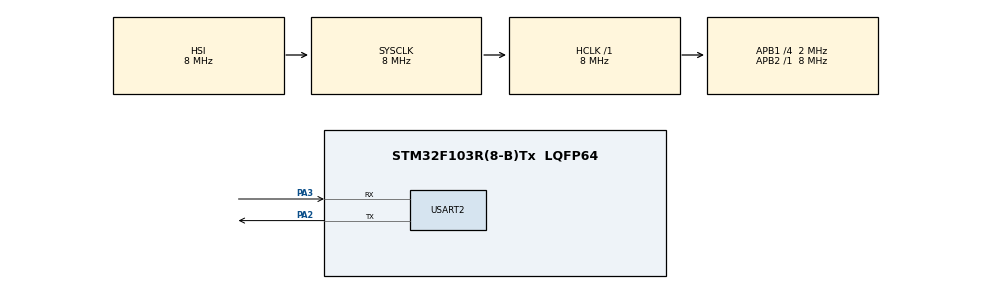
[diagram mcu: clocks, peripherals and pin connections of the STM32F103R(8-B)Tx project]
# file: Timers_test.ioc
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Mcu.Family=STM32F1
Mcu.Name=STM32F103R(8-B)Tx
Mcu.Package=LQFP64
NVIC.PriorityGroup=NVIC_PRIORITYGROUP_4
PA2.Mode=Asynchronous
PA2.Signal=USART2_TX
PA3.Mode=Asynchronous
PA3.Signal=USART2_RX
ProjectManager.HeapSize=0x200
ProjectManager.StackSize=0x400
ProjectManager.TargetToolchain=MDK-ARM V5
RCC.AHBFreq_Value=8000000
RCC.APB1CLKDivider=RCC_HCLK_DIV4
RCC.APB1Freq_Value=2000000
RCC.APB1TimFreq_Value=4000000
RCC.APB2Freq_Value=8000000
RCC.APB2TimFreq_Value=8000000
RCC.HCLKFreq_Value=8000000
RCC.RTCClockSelection=RCC_RTCCLKSOURCE_LSE
RCC.SYSCLKFreq_VALUE=8000000
RCC.USBFreq_Value=8000000
TIM2.ClockDivision=TIM_CLOCKDIVISION_DIV1
TIM2.Period=65535
TIM2.Prescaler=40-1
USART2.VirtualMode=VM_ASYNC
VP_SYS_VS_ND.Mode=No_Debug
VP_TIM2_VS_ClockSourceINT.Mode=Internal
board=NUCLEO-F103RB

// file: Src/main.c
/* USER CODE BEGIN Header */
/**
  ******************************************************************************
  * @file           : main.c
  * @brief          : Main program body
  ******************************************************************************
  ** This notice applies to any and all portions of this file
  * that are not between comment pairs USER CODE BEGIN and
  * USER CODE END. Other portions of this file, whether
  * inserted by the user or by software development tools
  * are owned by their respective copyright owners.
  *
  * COPYRIGHT(c) 2019 STMicroelectronics
  *
  * Redistribution and use in source and binary forms, with or without modification,
  * are permitted provided that the following conditions are met:
  *   1. Redistributions of source code must retain the above copyright notice,
  *      this list of conditions and the following disclaimer.
  *   2. Redistributions in binary form must reproduce the above copyright notice,
  *      this list of conditions and the following disclaimer in the documentation
  *      and/or other materials provided with the distribution.
  *   3. Neither the name of STMicroelectronics nor the names of its contributors
  *      may be used to endorse or promote products derived from this software
  *      without specific prior written permission.
  *
  * THIS SOFTWARE IS PROVIDED BY THE COPYRIGHT HOLDERS AND CONTRIBUTORS "AS IS"
  * AND ANY EXPRESS OR IMPLIED WARRANTIES, INCLUDING, BUT NOT LIMITED TO, THE
  * IMPLIED WARRANTIES OF MERCHANTABILITY AND FITNESS FOR A PARTICULAR PURPOSE ARE
  * DISCLAIMED. IN NO EVENT SHALL THE COPYRIGHT HOLDER OR CONTRIBUTORS BE LIABLE
  * FOR ANY DIRECT, INDIRECT, INCIDENTAL, SPECIAL, EXEMPLARY, OR CONSEQUENTIAL
  * DAMAGES (INCLUDING, BUT NOT LIMITED TO, PROCUREMENT OF SUBSTITUTE GOODS OR
  * SERVICES; LOSS OF USE, DATA, OR PROFITS; OR BUSINESS INTERRUPTION) HOWEVER
  * CAUSED AND ON ANY THEORY OF LIABILITY, WHETHER IN CONTRACT, STRICT LIABILITY,
  * OR TORT (INCLUDING NEGLIGENCE OR OTHERWISE) ARISING IN ANY WAY OUT OF THE USE
  * OF THIS SOFTWARE, EVEN IF ADVISED OF THE POSSIBILITY OF SUCH DAMAGE.
  *
  ******************************************************************************
  */
/* USER CODE END Header */

#include "main.h"

/* USER CODE BEGIN Includes */
#include <string.h>
/* USER CODE END Includes */

TIM_HandleTypeDef htim2;

UART_HandleTypeDef huart2;

void SystemClock_Config(void);
static void MX_GPIO_Init(void);
static void MX_TIM2_Init(void);
static void MX_USART2_UART_Init(void);

int main(void)
{

  /* MCU Configuration--------------------------------------------------------*/

  /* Reset of all peripherals, Initializes the Flash interface and the Systick. */
  HAL_Init();

  /* Configure the system clock */
  SystemClock_Config();

  /* Initialize all configured peripherals */
  MX_GPIO_Init();
  MX_TIM2_Init();
  MX_USART2_UART_Init();
  /* USER CODE BEGIN 2 */

	char transmit[20];

	HAL_TIM_Base_Start(&htim2);

	uint16_t last_time = 0;

  /* USER CODE END 2 */

  /* Infinite loop */
  while (1)
  {

    /* USER CODE BEGIN 3 */
		sprintf(transmit, "%u\r\n", (uint16_t)(TIM2->CNT - last_time));
		last_time = TIM2->CNT;
		HAL_UART_Transmit(&huart2, (uint8_t*)transmit, strlen(transmit), 10);

		HAL_Delay(100);
  }
  /* USER CODE END 3 */
}

void SystemClock_Config(void)
{
  RCC_OscInitTypeDef RCC_OscInitStruct = {0};
  RCC_ClkInitTypeDef RCC_ClkInitStruct = {0};

  /**Initializes the CPU, AHB and APB busses clocks
  */
  RCC_OscInitStruct.OscillatorType = RCC_OSCILLATORTYPE_HSI;
  RCC_OscInitStruct.HSIState = RCC_HSI_ON;
  RCC_OscInitStruct.HSICalibrationValue = RCC_HSICALIBRATION_DEFAULT;
  RCC_OscInitStruct.PLL.PLLState = RCC_PLL_NONE;
  if (HAL_RCC_OscConfig(&RCC_OscInitStruct) != HAL_OK)
  {
    Error_Handler();
  }
  /**Initializes the CPU, AHB and APB busses clocks
  */
  RCC_ClkInitStruct.ClockType = RCC_CLOCKTYPE_HCLK|RCC_CLOCKTYPE_SYSCLK
                              |RCC_CLOCKTYPE_PCLK1|RCC_CLOCKTYPE_PCLK2;
  RCC_ClkInitStruct.SYSCLKSource = RCC_SYSCLKSOURCE_HSI;
  RCC_ClkInitStruct.AHBCLKDivider = RCC_SYSCLK_DIV1;
  RCC_ClkInitStruct.APB1CLKDivider = RCC_HCLK_DIV4;
  RCC_ClkInitStruct.APB2CLKDivider = RCC_HCLK_DIV1;

  if (HAL_RCC_ClockConfig(&RCC_ClkInitStruct, FLASH_LATENCY_0) != HAL_OK)
  {
    Error_Handler();
  }
}

static void MX_TIM2_Init(void)
{

  TIM_ClockConfigTypeDef sClockSourceConfig = {0};
  TIM_MasterConfigTypeDef sMasterConfig = {0};

  htim2.Instance = TIM2;
  htim2.Init.Prescaler = 40-1;
  htim2.Init.CounterMode = TIM_COUNTERMODE_UP;
  htim2.Init.Period = 65535;
  htim2.Init.ClockDivision = TIM_CLOCKDIVISION_DIV1;
  htim2.Init.AutoReloadPreload = TIM_AUTORELOAD_PRELOAD_DISABLE;
  if (HAL_TIM_Base_Init(&htim2) != HAL_OK)
  {
    Error_Handler();
  }
  sClockSourceConfig.ClockSource = TIM_CLOCKSOURCE_INTERNAL;
  if (HAL_TIM_ConfigClockSource(&htim2, &sClockSourceConfig) != HAL_OK)
  {
    Error_Handler();
  }
  sMasterConfig.MasterOutputTrigger = TIM_TRGO_RESET;
  sMasterConfig.MasterSlaveMode = TIM_MASTERSLAVEMODE_DISABLE;
  if (HAL_TIMEx_MasterConfigSynchronization(&htim2, &sMasterConfig) != HAL_OK)
  {
    Error_Handler();
  }

}

static void MX_USART2_UART_Init(void)
{

  huart2.Instance = USART2;
  huart2.Init.BaudRate = 115200;
  huart2.Init.WordLength = UART_WORDLENGTH_8B;
  huart2.Init.StopBits = UART_STOPBITS_1;
  huart2.Init.Parity = UART_PARITY_NONE;
  huart2.Init.Mode = UART_MODE_TX_RX;
  huart2.Init.HwFlowCtl = UART_HWCONTROL_NONE;
  huart2.Init.OverSampling = UART_OVERSAMPLING_16;
  if (HAL_UART_Init(&huart2) != HAL_OK)
  {
    Error_Handler();
  }

}

static void MX_GPIO_Init(void)
{

  /* GPIO Ports Clock Enable */
  __HAL_RCC_GPIOA_CLK_ENABLE();

}

void Error_Handler(void)
{
}

/************************ (C) COPYRIGHT STMicroelectronics *****END OF FILE****/
